# RX64M_MPC_Pilot register map
File version: 1.0
RX64M_MPC_Pilot peripheral registers generated from iodefine.h (pilot).
Registers are 8-bit, read-write, reset 0x0 unless marked. A register's access mark holds for its fields unless they carry their own. Offsets are from the block's base; lines under a group give offsets from that group; [hi:lo] are bit positions; {n}, {i} and the like mark numbered series; 'fields as' and 'values as' point back to an identical list; <NAME> marks a mode.

## Memory map
0x0008C100 MPC size 0xD6

## MPC
Base 0x0008C100
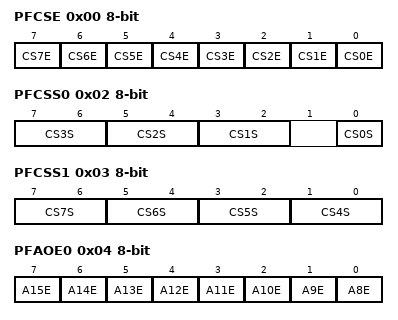
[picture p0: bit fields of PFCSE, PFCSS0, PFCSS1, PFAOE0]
0x00 PFCSE
  [n] CS{n}E (n=0..7)
0x02 PFCSS0
  [7:6] CS3S, [5:4] CS2S, [3:2] CS1S, [0] CS0S
0x03 PFCSS1
  [2n-7:2n-8] CS{n}S (n=4..7)
0x04 PFAOE0
  [n-8] A{n}E (n=8..15)
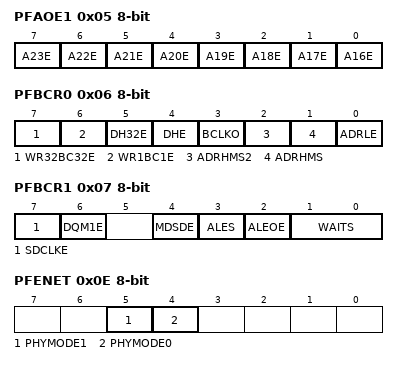
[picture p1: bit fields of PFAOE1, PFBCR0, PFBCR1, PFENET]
0x05 PFAOE1
  [n-16] A{n}E (n=16..23)
0x06 PFBCR0
  [7] WR32BC32E, [6] WR1BC1E, [5] DH32E, [4] DHE, [3] BCLKO, [2] ADRHMS2, [1] ADRHMS, [0] ADRLE
0x07 PFBCR1
  [7] SDCLKE, [6] DQM1E, [4] MDSDE, [3] ALES, [2] ALEOE, [1:0] WAITS
0x0E PFENET
  [5] PHYMODE1, [4] PHYMODE0
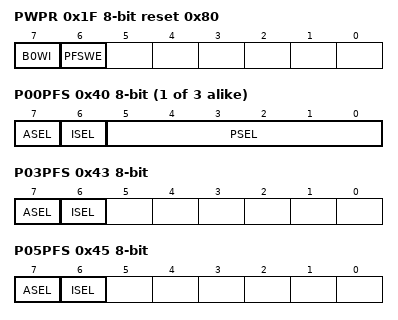
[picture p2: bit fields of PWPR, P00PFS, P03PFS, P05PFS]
0x1F PWPR reset 0x80
  [7] B0WI, [6] PFSWE
{0x40+i} P{i:02}PFS (i=0..2)
  [7] ASEL, [6] ISEL, [5:0] PSEL
0x43 P03PFS
  [7] ASEL, [6] ISEL
0x45 P05PFS
  [7] ASEL, [6] ISEL
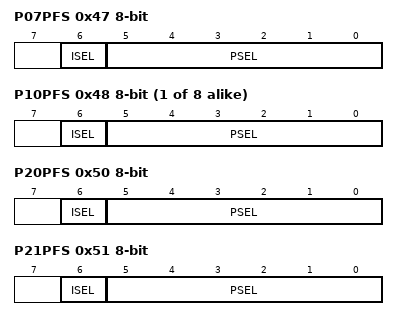
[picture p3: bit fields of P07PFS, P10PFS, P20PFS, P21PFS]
0x47 P07PFS
  [6] ISEL, [5:0] PSEL
{0x3E+i} P{i}PFS (i=10..17)
  [6] ISEL, [5:0] PSEL
0x50 P20PFS
  [6] ISEL, [5:0] PSEL
0x51 P21PFS
  [6] ISEL, [5:0] PSEL
{0x3C+i} P{i}PFS (i=22..27)
  [5:0] PSEL
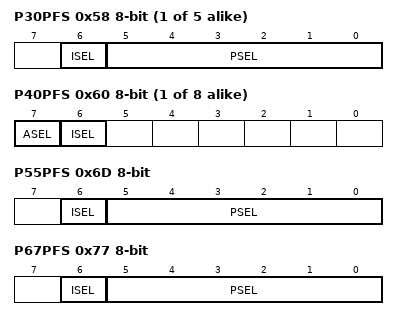
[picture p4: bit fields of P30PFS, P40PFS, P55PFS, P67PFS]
{0x3A+i} P{i}PFS (i=30..34)
  [6] ISEL, [5:0] PSEL
{0x38+i} P{i}PFS (i=40..47)
  [7] ASEL, [6] ISEL
{0x36+i} P{i}PFS (i=50..52)
  [5:0] PSEL
0x6C P54PFS
  [5:0] PSEL
0x6D P55PFS
  [6] ISEL, [5:0] PSEL
0x6E P56PFS
  [5:0] PSEL
0x70 P60PFS
  [5:0] PSEL
0x76 P66PFS
  [5:0] PSEL
0x77 P67PFS
  [6] ISEL, [5:0] PSEL
{0x32+i} P{i}PFS (i=71..77)
  [5:0] PSEL
{0x30+i} P{i}PFS (i=80..83)
  [5:0] PSEL
0x86 P86PFS
  [5:0] PSEL
0x87 P87PFS
  [5:0] PSEL
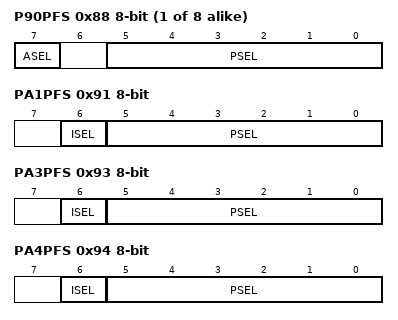
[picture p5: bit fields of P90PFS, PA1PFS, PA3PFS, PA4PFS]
{0x2E+i} P{i}PFS (i=90..97)
  [7] ASEL, [5:0] PSEL
0x90 PA0PFS
  [5:0] PSEL
0x91 PA1PFS
  [6] ISEL, [5:0] PSEL
0x92 PA2PFS
  [5:0] PSEL
0x93 PA3PFS
  [6] ISEL, [5:0] PSEL
0x94 PA4PFS
  [6] ISEL, [5:0] PSEL
{0x90+i} PA{i}PFS (i=5..7)
  [5:0] PSEL
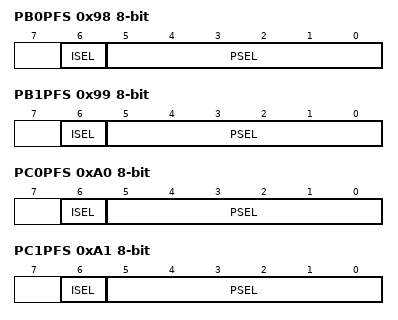
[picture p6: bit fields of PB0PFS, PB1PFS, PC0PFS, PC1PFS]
0x98 PB0PFS
  [6] ISEL, [5:0] PSEL
0x99 PB1PFS
  [6] ISEL, [5:0] PSEL
{0x98+i} PB{i}PFS (i=2..7)
  [5:0] PSEL
0xA0 PC0PFS
  [6] ISEL, [5:0] PSEL
0xA1 PC1PFS
  [6] ISEL, [5:0] PSEL
{0xA0+i} PC{i}PFS (i=2..5)
  [5:0] PSEL
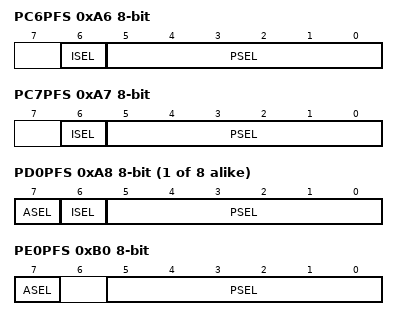
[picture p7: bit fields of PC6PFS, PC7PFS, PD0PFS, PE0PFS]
0xA6 PC6PFS
  [6] ISEL, [5:0] PSEL
0xA7 PC7PFS
  [6] ISEL, [5:0] PSEL
{0xA8+i} PD{i}PFS (i=0..7)
  [7] ASEL, [6] ISEL, [5:0] PSEL
0xB0 PE0PFS
  [7] ASEL, [5:0] PSEL
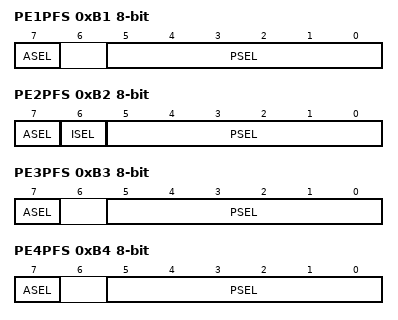
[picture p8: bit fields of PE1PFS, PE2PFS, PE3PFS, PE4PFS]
0xB1 PE1PFS
  [7] ASEL, [5:0] PSEL
0xB2 PE2PFS
  [7] ASEL, [6] ISEL, [5:0] PSEL
0xB3 PE3PFS
  [7] ASEL, [5:0] PSEL
0xB4 PE4PFS
  [7] ASEL, [5:0] PSEL
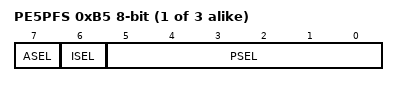
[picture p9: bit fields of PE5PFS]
{0xB0+i} PE{i}PFS (i=5..7)
  [7] ASEL, [6] ISEL, [5:0] PSEL
{0xB8+i} PF{i}PFS (i=0..2)
  [5:0] PSEL
0xBD PF5PFS
  [5:0] PSEL
{0xC0+i} PG{i}PFS (i=0..7)
  [5:0] PSEL
0xD3 PJ3PFS
  [5:0] PSEL
0xD5 PJ5PFS
  [5:0] PSEL
